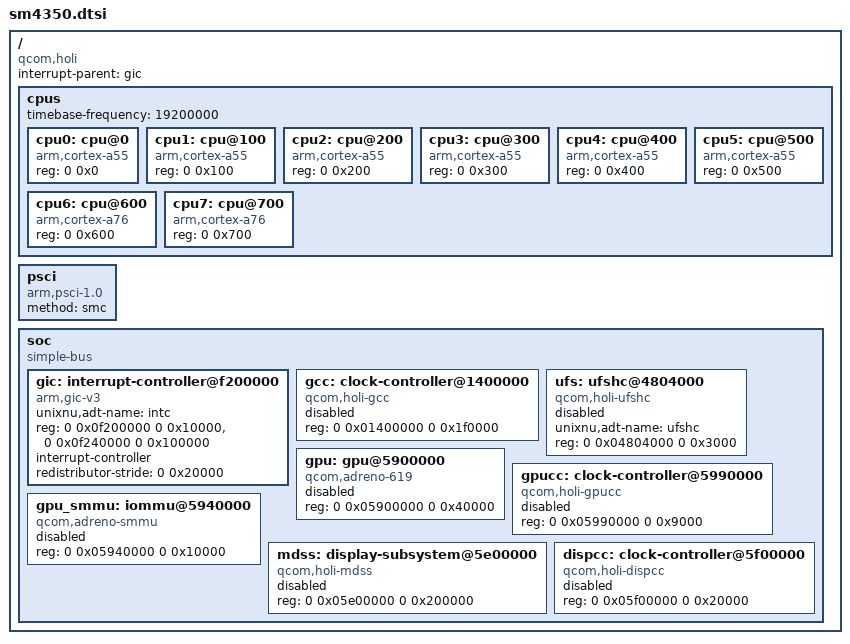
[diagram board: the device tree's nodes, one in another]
// SPDX-License-Identifier: BSD-3-Clause
// Qualcomm SM4350 (holi). Addresses from the moto g53 (penang) stock DTB and the penang XNU port.
/ {
    compatible = "qcom,holi";
    #address-cells = <2>;
    #size-cells = <2>;
    interrupt-parent = <&gic>;

    cpus {
        #address-cells = <2>;
        #size-cells = <0>;
        timebase-frequency = <19200000>;
        cpu0: cpu@0 { device_type = "cpu"; compatible = "arm,cortex-a55"; reg = <0 0x0>; };
        cpu1: cpu@100 { device_type = "cpu"; compatible = "arm,cortex-a55"; reg = <0 0x100>; };
        cpu2: cpu@200 { device_type = "cpu"; compatible = "arm,cortex-a55"; reg = <0 0x200>; };
        cpu3: cpu@300 { device_type = "cpu"; compatible = "arm,cortex-a55"; reg = <0 0x300>; };
        cpu4: cpu@400 { device_type = "cpu"; compatible = "arm,cortex-a55"; reg = <0 0x400>; };
        cpu5: cpu@500 { device_type = "cpu"; compatible = "arm,cortex-a55"; reg = <0 0x500>; };
        cpu6: cpu@600 { device_type = "cpu"; compatible = "arm,cortex-a76"; reg = <0 0x600>; };
        cpu7: cpu@700 { device_type = "cpu"; compatible = "arm,cortex-a76"; reg = <0 0x700>; };
    };

    psci { compatible = "arm,psci-1.0"; method = "smc"; };

    soc {
        compatible = "simple-bus";
        #address-cells = <2>;
        #size-cells = <2>;
        ranges;

        gic: interrupt-controller@f200000 {
            compatible = "arm,gic-v3";
            unixnu,adt-name = "intc";
            reg = <0 0x0f200000 0 0x10000>, <0 0x0f240000 0 0x100000>;
            #interrupt-cells = <4>;
            #address-cells = <0>;
            interrupt-controller;
            redistributor-stride = <0 0x20000>;
        };

        gcc: clock-controller@1400000 {
            compatible = "qcom,holi-gcc";
            reg = <0 0x01400000 0 0x1f0000>;
            status = "disabled";
        };

        ufs: ufshc@4804000 {
            compatible = "qcom,holi-ufshc";
            unixnu,adt-name = "ufshc";
            reg = <0 0x04804000 0 0x3000>;
            status = "disabled";
        };

        gpu: gpu@5900000 {
            compatible = "qcom,adreno-619", "qcom,adreno";
            reg = <0 0x05900000 0 0x40000>;
            reg-names = "kgsl_3d0_reg_memory";
            status = "disabled";
        };

        gpucc: clock-controller@5990000 {
            compatible = "qcom,holi-gpucc";
            reg = <0 0x05990000 0 0x9000>;
            status = "disabled";
        };

        gpu_smmu: iommu@5940000 {
            compatible = "qcom,adreno-smmu";
            reg = <0 0x05940000 0 0x10000>;
            status = "disabled";
        };

        mdss: display-subsystem@5e00000 {
            compatible = "qcom,holi-mdss";
            reg = <0 0x05e00000 0 0x200000>;
            status = "disabled";
        };

        dispcc: clock-controller@5f00000 {
            compatible = "qcom,holi-dispcc";
            reg = <0 0x05f00000 0 0x20000>;
            status = "disabled";
        };
    };
};
